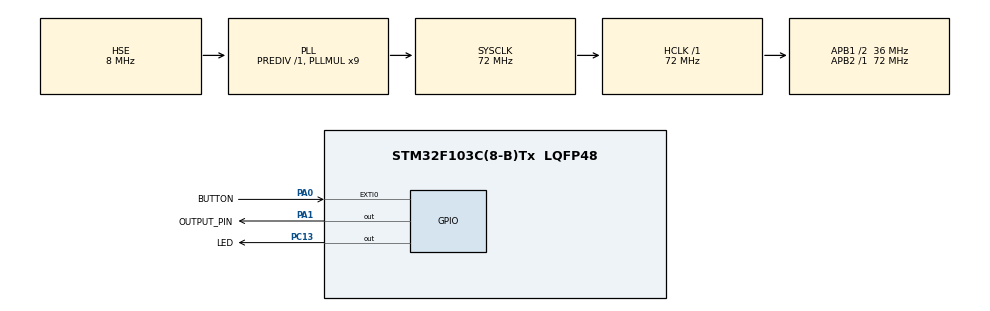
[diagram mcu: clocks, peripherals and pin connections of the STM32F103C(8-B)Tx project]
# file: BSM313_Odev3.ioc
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Mcu.Family=STM32F1
Mcu.Name=STM32F103C(8-B)Tx
Mcu.Package=LQFP48
NVIC.EXTI0_IRQn=true\:0\:0\:false\:false\:true\:true\:true\:true
NVIC.PriorityGroup=NVIC_PRIORITYGROUP_4
NVIC.TIM2_IRQn=true\:0\:0\:false\:false\:true\:true\:true\:true
PA0-WKUP.GPIO_Label=BUTTON 
PA0-WKUP.GPIO_PuPd=GPIO_PULLUP
PA0-WKUP.Signal=GPXTI0
PA1.GPIO_Label=OUTPUT_PIN
PA1.Signal=GPIO_Output
PC13-TAMPER-RTC.GPIO_Label=LED
PC13-TAMPER-RTC.Signal=GPIO_Output
PD0-OSC_IN.Mode=HSE-External-Oscillator
PD0-OSC_IN.Signal=RCC_OSC_IN
PD1-OSC_OUT.Mode=HSE-External-Oscillator
PD1-OSC_OUT.Signal=RCC_OSC_OUT
ProjectManager.HeapSize=0x200
ProjectManager.StackSize=0x400
ProjectManager.TargetToolchain=Makefile
RCC.AHBFreq_Value=72000000
RCC.APB1CLKDivider=RCC_HCLK_DIV2
RCC.APB1Freq_Value=36000000
RCC.APB1TimFreq_Value=72000000
RCC.APB2Freq_Value=72000000
RCC.APB2TimFreq_Value=72000000
RCC.HCLKFreq_Value=72000000
RCC.PLLMUL=RCC_PLL_MUL9
RCC.PLLSourceVirtual=RCC_PLLSOURCE_HSE
RCC.SYSCLKFreq_VALUE=72000000
RCC.SYSCLKSource=RCC_SYSCLKSOURCE_PLLCLK
RCC.USBFreq_Value=72000000
TIM2.Period=8999
TIM2.Prescaler=7999
VP_SYS_VS_ND.Mode=No_Debug
VP_TIM2_VS_ClockSourceINT.Mode=Internal
board=custom

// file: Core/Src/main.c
/* USER CODE BEGIN Header */
/**
  ******************************************************************************
  * @file           : main.c
  * @brief          : Main program body
  ******************************************************************************
  * @attention
  *
  * Copyright (c) 2026 STMicroelectronics.
  * All rights reserved.
  *
  * This software is licensed under terms that can be found in the LICENSE file
  * in the root directory of this software component.
  * If no LICENSE file comes with this software, it is provided AS-IS.
  *
  ******************************************************************************
  */
/* USER CODE END Header */
#include "main.h"

/* USER CODE BEGIN Includes */

#include <stdint.h>

#include "stm32f1xx_hal_flash_ex.h"

/*
 * BSM316 / ÖDEV 3 (Summary)
 * - TIM2 @ 1 Hz interrupt drives the whole timing (no HAL_Delay).
 * - PC13 LED blinks blink_count times (1s ON, 1s OFF) then stays OFF for 5s; repeats forever.
 * - Button on PA0 updates blink_count in range [4..7] with wrap (7 -> 4).
 * - blink_count is loaded from internal flash at boot, and written back on every change.
 * - If stored value is erased/invalid (>7), default to 4 and write 4 to flash.
 * - Factory reset: if button is held continuously from startup for >= 3 seconds,
 *   blink_count becomes 4 (factory default).
 * - PA1 is configured as GPIO output and remains LOW for the entire runtime.
 *
 * NOTE about wiring:
 * This firmware expects an active-low button on PA0:
 *   PA0 = input pull-up, EXTI on FALLING edge, button connects PA0 to GND when pressed.
 * If you don't have a button/breadboard, you can touch the A0 and A1 header pads together
 * briefly (PA1 is held LOW) to emulate a button press on PA0.
 */

/* USER CODE END Includes */

/* USER CODE BEGIN PD */

#define BLINK_COUNT_MIN                (4u)
#define BLINK_COUNT_MAX                (7u)

/* Bluepill PC13 LED is typically active-low. */
#define LED_ON()   HAL_GPIO_WritePin(LED_GPIO_Port, LED_Pin, GPIO_PIN_RESET)
#define LED_OFF()  HAL_GPIO_WritePin(LED_GPIO_Port, LED_Pin, GPIO_PIN_SET)

/* Reserve last flash page for persistent user data (see STM32F103XX_FLASH.ld). */
#define FLASH_BLINK_COUNT_ADDR        (0x0800FC00u)

/* USER CODE END PD */

TIM_HandleTypeDef htim2;

/* USER CODE BEGIN PV */

/* Ödev 3: blink_count runtime value (must stay in [4..7]). */
static volatile uint16_t g_blink_count = BLINK_COUNT_MIN;

typedef enum
{
  BLINK_STATE_ON = 0,
  BLINK_STATE_OFF,
  BLINK_STATE_PAUSE
} BlinkState;

static volatile BlinkState g_blink_state = BLINK_STATE_ON;
static volatile uint8_t g_blinks_done = 0;
static volatile uint8_t g_pause_remaining = 0;

/* Flash persistence (write from main loop, not from ISR). */
static volatile uint8_t g_flash_write_pending = 0;
static volatile uint16_t g_flash_value_pending = BLINK_COUNT_MIN;

/* Factory reset detection during startup window.
 * We detect a continuous >=3s press within the first few seconds after boot.
 */
static volatile uint8_t g_startup_check_active = 1;
static uint32_t g_startup_window_start_tick = 0u;
static uint32_t g_startup_press_start_tick = 0u;
static uint8_t g_startup_press_tracking = 0u;

/* USER CODE END PV */

void SystemClock_Config(void);
static void MX_GPIO_Init(void);
static void MX_TIM2_Init(void);
/* USER CODE BEGIN PFP */
static void Blink_ResetCycle(void);

static uint16_t Flash_ReadBlinkCount(void);
static HAL_StatusTypeDef Flash_WriteBlinkCount(uint16_t value);

/* USER CODE END PFP */

/* USER CODE BEGIN 0 */

static void Blink_ResetCycle(void)
{
  /* Ödev 3: restart the repeating pattern using the current g_blink_count. */
  __disable_irq();
  g_blinks_done = 0;
  g_pause_remaining = 0;

  /* Start with LED on immediately for the first 1-second window. */
  LED_ON();
  g_blink_state = BLINK_STATE_OFF;
  __enable_irq();
}

static uint16_t Flash_ReadBlinkCount(void)
{
  return *((volatile const uint16_t *)FLASH_BLINK_COUNT_ADDR);
}

static HAL_StatusTypeDef Flash_WriteBlinkCount(uint16_t value)
{
  HAL_StatusTypeDef status = HAL_OK;
  FLASH_EraseInitTypeDef eraseInit = {0};
  uint32_t pageError = 0;

  __disable_irq();
  if (HAL_FLASH_Unlock() != HAL_OK)
  {
    __enable_irq();
    return HAL_ERROR;
  }

  eraseInit.TypeErase = FLASH_TYPEERASE_PAGES;
  eraseInit.PageAddress = FLASH_BLINK_COUNT_ADDR;
  eraseInit.NbPages = 1;
  status = HAL_FLASHEx_Erase(&eraseInit, &pageError);
  if (status == HAL_OK)
  {
    status = HAL_FLASH_Program(FLASH_TYPEPROGRAM_HALFWORD, FLASH_BLINK_COUNT_ADDR, (uint64_t)value);
  }

  (void)HAL_FLASH_Lock();
  __enable_irq();
  return status;
}

/* USER CODE END 0 */

int main(void)
{

  /* MCU Configuration--------------------------------------------------------*/

  /* Reset of all peripherals, Initializes the Flash interface and the Systick. */
  HAL_Init();

  /* Configure the system clock */
  SystemClock_Config();

  /* Initialize all configured peripherals */
  MX_GPIO_Init();
  MX_TIM2_Init();
  /* USER CODE BEGIN 2 */

  /* Load blink_count from internal flash (persistent). If erased/invalid (>7), default to 4
   * and update flash to 4.
   */
  {
    uint16_t stored = Flash_ReadBlinkCount();
    if ((stored < BLINK_COUNT_MIN) || (stored > BLINK_COUNT_MAX))
    {
      g_blink_count = BLINK_COUNT_MIN;
      g_flash_value_pending = BLINK_COUNT_MIN;
      g_flash_write_pending = 1u;
    }
    else
    {
      g_blink_count = stored;
    }
  }

  /* Factory reset condition at boot: if the button is held continuously for the
    * startup window, blink_count is reset to 4.
   */
  g_startup_check_active = 1u;
    g_startup_window_start_tick = HAL_GetTick();
    g_startup_press_start_tick = 0u;
    g_startup_press_tracking = 0u;

  LED_OFF();
  Blink_ResetCycle();

  /* Ödev 3 (Requirement): TIM2 configured to generate 1 Hz interrupts.
   * (See MX_TIM2_Init: Prescaler=7999, Period=8999 for 72MHz timer clock.)
   */
  HAL_TIM_Base_Start_IT(&htim2);

  /* USER CODE END 2 */

  /* Infinite loop */
  /* USER CODE BEGIN WHILE */
  while (1)
  {
    __WFI();

    /* Factory reset: if button is held >=3s within the startup window.
     * This runs in the main loop using SysTick time base for robustness.
     */
    if (g_startup_check_active != 0u)
    {
      uint32_t now = HAL_GetTick();
      if ((now - g_startup_window_start_tick) > 5000u)
      {
        g_startup_check_active = 0u;
        g_startup_press_tracking = 0u;
      }
      else
      {
        uint8_t pressed = (HAL_GPIO_ReadPin(BUTTON_GPIO_Port, BUTTON_Pin) == GPIO_PIN_RESET) ? 1u : 0u;
        if (pressed != 0u)
        {
          if (g_startup_press_tracking == 0u)
          {
            g_startup_press_tracking = 1u;
            g_startup_press_start_tick = now;
          }
          else if ((now - g_startup_press_start_tick) >= 3000u)
          {
            g_blink_count = BLINK_COUNT_MIN;
            g_flash_value_pending = BLINK_COUNT_MIN;
            g_flash_write_pending = 1u;
            Blink_ResetCycle();
            g_startup_check_active = 0u;
          }
        }
        else
        {
          g_startup_press_tracking = 0u;
        }
      }
    }

    /* Handle pending flash write outside interrupt context. */
    if (g_flash_write_pending != 0u)
    {
      uint16_t value = g_flash_value_pending;
      if (Flash_WriteBlinkCount(value) == HAL_OK)
      {
        g_flash_write_pending = 0u;
      }
    }
    /* USER CODE END WHILE */

  }
}

void SystemClock_Config(void)
{
  RCC_OscInitTypeDef RCC_OscInitStruct = {0};
  RCC_ClkInitTypeDef RCC_ClkInitStruct = {0};

  /** Initializes the RCC Oscillators according to the specified parameters
  * in the RCC_OscInitTypeDef structure.
  */
  RCC_OscInitStruct.OscillatorType = RCC_OSCILLATORTYPE_HSE;
  RCC_OscInitStruct.HSEState = RCC_HSE_ON;
  RCC_OscInitStruct.HSEPredivValue = RCC_HSE_PREDIV_DIV1;
  RCC_OscInitStruct.HSIState = RCC_HSI_ON;
  RCC_OscInitStruct.PLL.PLLState = RCC_PLL_ON;
  RCC_OscInitStruct.PLL.PLLSource = RCC_PLLSOURCE_HSE;
  RCC_OscInitStruct.PLL.PLLMUL = RCC_PLL_MUL9;
  if (HAL_RCC_OscConfig(&RCC_OscInitStruct) != HAL_OK)
  {
    Error_Handler();
  }

  /** Initializes the CPU, AHB and APB buses clocks
  */
  RCC_ClkInitStruct.ClockType = RCC_CLOCKTYPE_HCLK|RCC_CLOCKTYPE_SYSCLK
                              |RCC_CLOCKTYPE_PCLK1|RCC_CLOCKTYPE_PCLK2;
  RCC_ClkInitStruct.SYSCLKSource = RCC_SYSCLKSOURCE_PLLCLK;
  RCC_ClkInitStruct.AHBCLKDivider = RCC_SYSCLK_DIV1;
  RCC_ClkInitStruct.APB1CLKDivider = RCC_HCLK_DIV2;
  RCC_ClkInitStruct.APB2CLKDivider = RCC_HCLK_DIV1;

  if (HAL_RCC_ClockConfig(&RCC_ClkInitStruct, FLASH_LATENCY_2) != HAL_OK)
  {
    Error_Handler();
  }
}

static void MX_TIM2_Init(void)
{

  TIM_ClockConfigTypeDef sClockSourceConfig = {0};
  TIM_MasterConfigTypeDef sMasterConfig = {0};

  htim2.Instance = TIM2;
  htim2.Init.Prescaler = 7999;
  htim2.Init.CounterMode = TIM_COUNTERMODE_UP;
  htim2.Init.Period = 8999;
  htim2.Init.ClockDivision = TIM_CLOCKDIVISION_DIV1;
  htim2.Init.AutoReloadPreload = TIM_AUTORELOAD_PRELOAD_DISABLE;
  if (HAL_TIM_Base_Init(&htim2) != HAL_OK)
  {
    Error_Handler();
  }
  sClockSourceConfig.ClockSource = TIM_CLOCKSOURCE_INTERNAL;
  if (HAL_TIM_ConfigClockSource(&htim2, &sClockSourceConfig) != HAL_OK)
  {
    Error_Handler();
  }
  sMasterConfig.MasterOutputTrigger = TIM_TRGO_RESET;
  sMasterConfig.MasterSlaveMode = TIM_MASTERSLAVEMODE_DISABLE;
  if (HAL_TIMEx_MasterConfigSynchronization(&htim2, &sMasterConfig) != HAL_OK)
  {
    Error_Handler();
  }

}

static void MX_GPIO_Init(void)
{
  GPIO_InitTypeDef GPIO_InitStruct = {0};

  /* GPIO Ports Clock Enable */
  __HAL_RCC_GPIOC_CLK_ENABLE();
  __HAL_RCC_GPIOD_CLK_ENABLE();
  __HAL_RCC_GPIOA_CLK_ENABLE();

  /*Configure GPIO pin Output Level */
  HAL_GPIO_WritePin(LED_GPIO_Port, LED_Pin, GPIO_PIN_SET);

  /*Configure GPIO pin Output Level */
  HAL_GPIO_WritePin(OUTPUT_PIN_GPIO_Port, OUTPUT_PIN_Pin, GPIO_PIN_RESET);

  /*Configure GPIO pin : LED_Pin */
  GPIO_InitStruct.Pin = LED_Pin;
  GPIO_InitStruct.Mode = GPIO_MODE_OUTPUT_PP;
  GPIO_InitStruct.Pull = GPIO_NOPULL;
  GPIO_InitStruct.Speed = GPIO_SPEED_FREQ_LOW;
  HAL_GPIO_Init(LED_GPIO_Port, &GPIO_InitStruct);

  /*Configure GPIO pin : BUTTON_Pin */
  GPIO_InitStruct.Pin = BUTTON_Pin;
  GPIO_InitStruct.Mode = GPIO_MODE_IT_FALLING;
  GPIO_InitStruct.Pull = GPIO_PULLUP;
  HAL_GPIO_Init(BUTTON_GPIO_Port, &GPIO_InitStruct);

  /*Configure GPIO pin : OUTPUT_PIN_Pin */
  GPIO_InitStruct.Pin = OUTPUT_PIN_Pin;
  GPIO_InitStruct.Mode = GPIO_MODE_OUTPUT_PP;
  GPIO_InitStruct.Pull = GPIO_NOPULL;
  GPIO_InitStruct.Speed = GPIO_SPEED_FREQ_LOW;
  HAL_GPIO_Init(OUTPUT_PIN_GPIO_Port, &GPIO_InitStruct);

  /* EXTI interrupt init*/
  HAL_NVIC_SetPriority(EXTI0_IRQn, 0, 0);
  HAL_NVIC_EnableIRQ(EXTI0_IRQn);

}

/* USER CODE BEGIN 4 */

void HAL_TIM_PeriodElapsedCallback(TIM_HandleTypeDef *htim)
{
  if (htim->Instance != TIM2)
  {
    return;
  }

  /* Ödev 3 (Requirement): TIM2 must generate 1 interrupt per second.
   * This callback is executed once per second.
   */
  /* Ödev 3 (Requirement):
   * - LED blinks blink_count times (1-second ON / 1-second OFF)
   * - then stays OFF for 5 seconds
   * - then repeats forever
   */
  switch (g_blink_state)
  {
    case BLINK_STATE_ON:
      LED_ON();
      g_blink_state = BLINK_STATE_OFF;
      break;

    case BLINK_STATE_OFF:
      LED_OFF();
      if (g_blinks_done < 0xFFu)
      {
        g_blinks_done++;
      }
      if (g_blinks_done >= (uint8_t)g_blink_count)
      {
        g_blink_state = BLINK_STATE_PAUSE;
        g_pause_remaining = 5u;
      }
      else
      {
        g_blink_state = BLINK_STATE_ON;
      }
      break;

    case BLINK_STATE_PAUSE:
    default:
      LED_OFF();
      if (g_pause_remaining > 0u)
      {
        g_pause_remaining--;
      }
      if (g_pause_remaining == 0u)
      {
        g_blinks_done = 0;
        g_blink_state = BLINK_STATE_ON;
      }
      break;
  }
}

void HAL_GPIO_EXTI_Callback(uint16_t GPIO_Pin)
{
  if (GPIO_Pin != BUTTON_Pin)
  {
    return;
  }

  /* Simple debounce using system tick. */
  static uint32_t lastPressTick = 0u;
  uint32_t now = HAL_GetTick();
  if ((now - lastPressTick) < 200u)
  {
    return;
  }
  lastPressTick = now;

  if (g_blink_count < BLINK_COUNT_MAX)
  {
    g_blink_count++;
  }
  else
  {
    g_blink_count = BLINK_COUNT_MIN;
  }

  /* Persist and restart blink cycle with the new count. */
  g_flash_value_pending = (uint16_t)g_blink_count;
  g_flash_write_pending = 1u;
  Blink_ResetCycle();
}

/* USER CODE END 4 */

void Error_Handler(void)
{
  __disable_irq();
  while (1)
  {
  }
}
